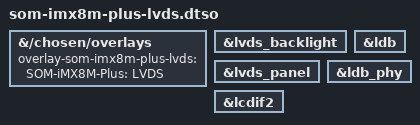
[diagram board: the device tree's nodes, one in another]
#include "overlay.h"

&{/chosen/overlays} {
	overlay-som-imx8m-plus-lvds = "SOM-iMX8M-Plus: LVDS";
};

&lvds_backlight {
	status = "okay";
};

&lvds_panel {
	status = "okay";
};

&ldb {
	status = "okay";
};

&ldb_phy {
	status = "okay";
};

&lcdif2 {
	status = "okay";
};
